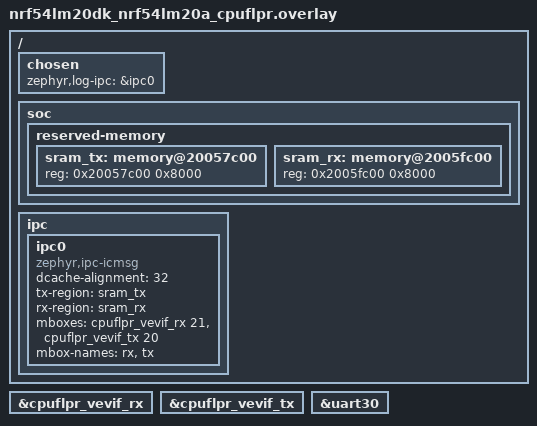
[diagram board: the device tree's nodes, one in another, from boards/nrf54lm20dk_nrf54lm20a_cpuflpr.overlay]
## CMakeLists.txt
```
#
# Copyright (c) 2026 Nordic Semiconductor
#
# SPDX-License-Identifier: LicenseRef-Nordic-5-Clause
#

cmake_minimum_required(VERSION 3.20.0)

find_package(Zephyr REQUIRED HINTS $ENV{ZEPHYR_BASE})
project(multidomain_backends_remote)

target_sources(app PRIVATE
  src/main.c
  src/cpuflpr_verbose.c
)
```

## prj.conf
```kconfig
CONFIG_ASSERT=y
CONFIG_HEAP_MEM_POOL_SIZE=2048

CONFIG_IPC_SERVICE=y
CONFIG_IPC_SERVICE_BACKEND_ICMSG=y
CONFIG_MBOX=y
CONFIG_PBUF_RX_READ_BUF_SIZE=256
CONFIG_IPC_SERVICE_BACKEND_ICMSG_WQ_STACK_SIZE=2048

CONFIG_LOG=y
CONFIG_LOG_MODE_DEFERRED=y
CONFIG_LOG_RUNTIME_FILTERING=y
CONFIG_LOG_BUFFER_SIZE=4096
CONFIG_LOG_MAX_LEVEL=3
CONFIG_LOG_DEFAULT_LEVEL=3
CONFIG_LOG_OVERRIDE_LEVEL=3
CONFIG_LOG_DOMAIN_NAME="cpuflpr"
CONFIG_LOG_BACKEND_IPC_SERVICE=y
CONFIG_LOG_BACKEND_UART=n
CONFIG_LOG_BACKEND_RTT=n

CONFIG_MAIN_STACK_SIZE=2048
CONFIG_BOOT_BANNER=n
CONFIG_SIZE_OPTIMIZATIONS=y
```

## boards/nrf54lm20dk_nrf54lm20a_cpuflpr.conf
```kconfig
CONFIG_LOG=y
CONFIG_LOG_MODE_DEFERRED=y
CONFIG_ASSERT=n
CONFIG_LOG_BACKEND_UART=n

CONFIG_EARLY_CONSOLE=y
CONFIG_HEAP_MEM_POOL_SIZE=1024
CONFIG_SIZE_OPTIMIZATIONS=y
```

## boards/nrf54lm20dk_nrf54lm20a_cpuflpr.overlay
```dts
/*
 * Copyright (c) 2026 Nordic Semiconductor
 *
 * SPDX-License-Identifier: LicenseRef-Nordic-5-Clause
 */

/ {
	chosen {
		zephyr,log-ipc = &ipc0;
	};

	soc {
		reserved-memory {
			#address-cells = <1>;
			#size-cells = <1>;

			sram_tx: memory@20057c00 {
				reg = <0x20057c00 0x8000>;
			};

			sram_rx: memory@2005fc00 {
				reg = <0x2005fc00 0x8000>;
			};
		};
	};

	ipc {
		ipc0: ipc0 {
			compatible = "zephyr,ipc-icmsg";
			dcache-alignment = <32>;
			tx-region = <&sram_tx>;
			rx-region = <&sram_rx>;
			mboxes = <&cpuflpr_vevif_rx 21>, <&cpuflpr_vevif_tx 20>;
			mbox-names = "rx", "tx";
			status = "okay";
		};
	};
};

&cpuflpr_vevif_rx {
	status = "okay";
};

&cpuflpr_vevif_tx {
	status = "okay";
};

&uart30 {
	/delete-property/ hw-flow-control;
};
```

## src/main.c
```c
/*
 * Copyright (c) 2026 Nordic Semiconductor
 *
 * SPDX-License-Identifier: LicenseRef-Nordic-5-Clause
 */

#include <stdint.h>

#include <zephyr/kernel.h>
#include <zephyr/logging/log.h>

#include "cpuflpr_verbose.h"

LOG_MODULE_REGISTER(cpuflpr_main, LOG_LEVEL_INF);

int main(void)
{
	uint32_t seq = 0U;

	LOG_INF("cpuflpr domain started (%s)", CONFIG_BOARD);
	LOG_INF("cpuflpr demo cadence: app logs every 10 seconds");

	while (1) {
		LOG_INF("cpuflpr info heartbeat seq=%u (10s cadence)", seq);
		if ((seq % 3U) == 0U) {
			LOG_WRN("cpuflpr warning checkpoint seq=%u", seq);
		}
		if ((seq % 6U) == 0U) {
			LOG_ERR("cpuflpr error checkpoint seq=%u", seq);
		}

		cpuflpr_verbose_log(seq);

		seq++;
		k_sleep(K_SECONDS(10));
	}

	return 0;
}
```

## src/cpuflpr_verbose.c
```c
/*
 * Copyright (c) 2026 Nordic Semiconductor
 *
 * SPDX-License-Identifier: LicenseRef-Nordic-5-Clause
 */

#include <zephyr/logging/log.h>
#include "cpuflpr_verbose.h"

LOG_MODULE_REGISTER(cpuflpr_verbose, LOG_LEVEL_INF);

void cpuflpr_verbose_log(uint32_t seq)
{
	if ((seq % 4U) == 0U) {
		LOG_INF("cpuflpr verbose info seq=%u", seq);
	}
}
```

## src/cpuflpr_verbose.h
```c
/*
 * Copyright (c) 2026 Nordic Semiconductor
 *
 * SPDX-License-Identifier: LicenseRef-Nordic-5-Clause
 */

#ifndef CPUFLPR_VERBOSE_H_
#define CPUFLPR_VERBOSE_H_

#include <stdint.h>

void cpuflpr_verbose_log(uint32_t seq);

#endif /* CPUFLPR_VERBOSE_H_ */
```
